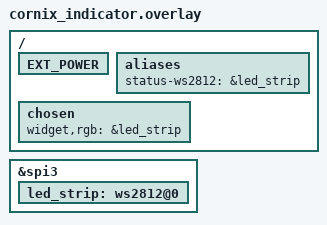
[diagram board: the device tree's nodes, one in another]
// #include <zephyr/dt-bindings/led/led.h>
&spi3 {
    status = "okay";

   led_strip: ws2812@0 {
        status = "okay";
    };
};

/ {

    EXT_POWER {
        status = "okay";
    };

    aliases {
        status-ws2812 = &led_strip;
    };

    chosen {
		  widget,rgb = &led_strip;
    };
};

//vim: set ft=dts:
